# TimerDemo register map
File version: 1.0
Registers are 32-bit, read-write, reset 0x0 unless marked. A register's access mark holds for its fields unless they carry their own. Offsets are from the block's base; lines under a group give offsets from that group; [hi:lo] are bit positions; {n}, {i} and the like mark numbered series; 'fields as' and 'values as' point back to an identical list; <NAME> marks a mode.

## Memory map
0x40000000 TIMER0
0x40000100 TIMER1

## TIMER0
Base 0x40000000
Same registers: TIMER1 0x40000100
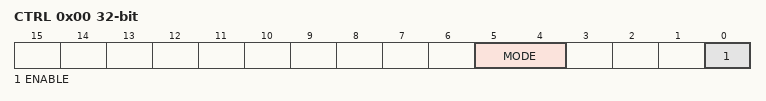
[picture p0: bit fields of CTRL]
0x00 CTRL
  [5:4] MODE, [0] ENABLE
{0x10+4i} CAPTURE[{i}] (i=0..1) ro
